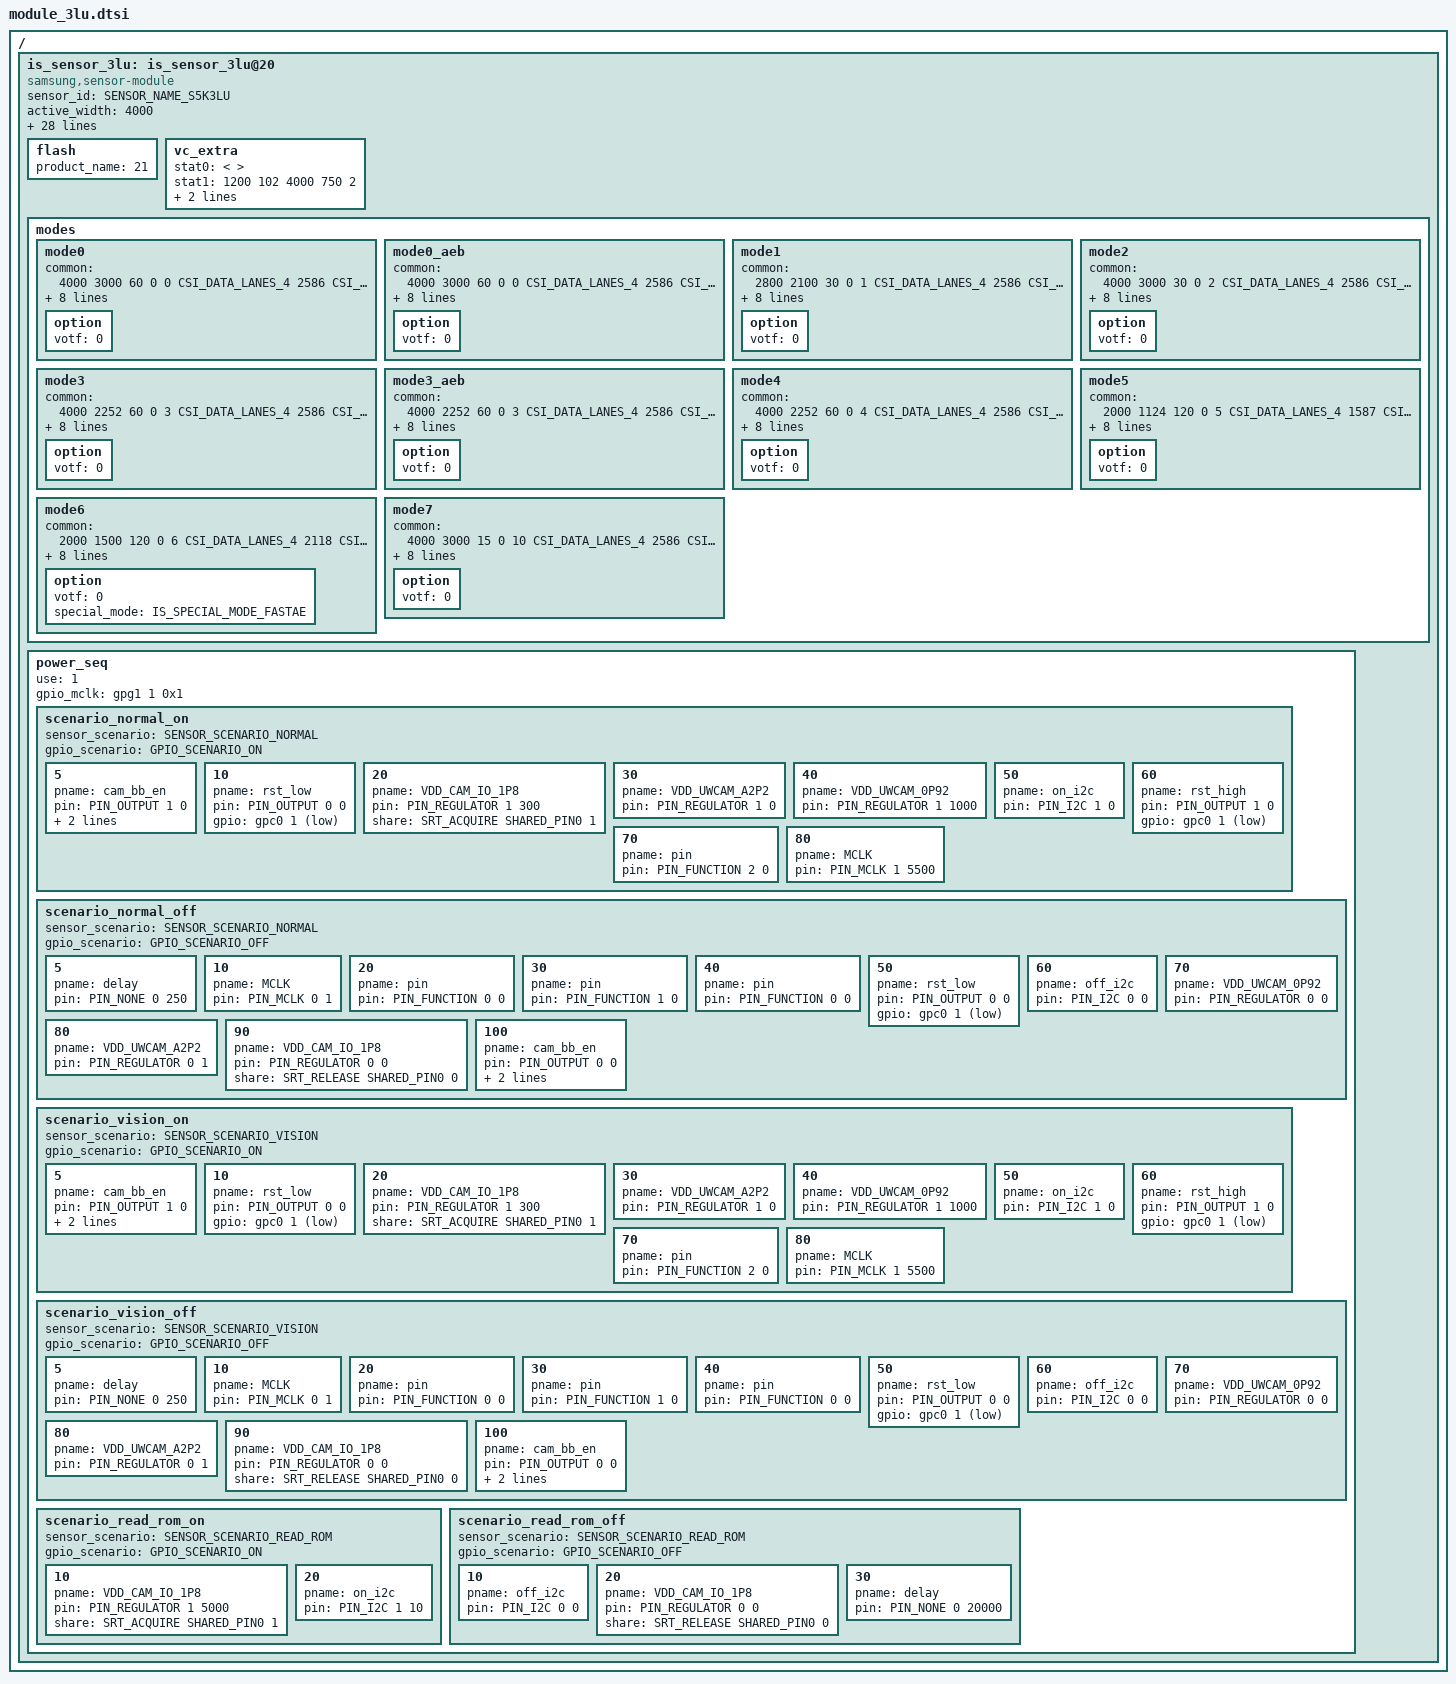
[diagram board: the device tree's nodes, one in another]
/*
 * SAMSUNG EXYNOSxxxx board camera device tree source
 *
 * Copyright (c) 2024 Samsung Electronics Co., Ltd.
 *		http://www.samsung.com
 *
 * This program is free software; you can redistribute it and/or modify
 * it under the terms of the GNU General Public License version 2 as
 * published by the Free Software Foundation.
 */

#include <dt-bindings/camera/exynos_is_dt.h>

/ {
	fragment@camera {
		target-path = "/";
		__overlay__ {
			is_sensor_3lu: is_sensor_3lu@20 {
				compatible = "samsung,sensor-module";

				/* common */
				sensor_id = <SENSOR_NAME_S5K3LU>;
				active_width = <4000>;
				active_height = <3000>;
				margin_left = <0>;
				margin_right = <0>;
				margin_top = <0>;
				margin_bottom = <0>;
				max_framerate = <240>;
				bitwidth = <10>;
				use_retention_mode = <SENSOR_RETENTION_UNSUPPORTED>;
				sensor_maker = "SLSI";
				sensor_name = "S5K3LU";
				setfile_name = "setfile_3lu.bin";
				pinning_setfile;
				status = "okay";

				/* board */
				pinctrl-names = "pin0", "pin1", "pin2", "release";
				pinctrl-0 = <>;
				pinctrl-1 = <&sensor_mclk1_out>;
				pinctrl-2 = <&sensor_mclk1_fn>;
				pinctrl-3 = <>;

				position = <4>;	/* Rear:0. Front:1. Rear_sub:2. Secure:3. */
				id = <4>; /* is_sensor id */
				mclk_ch = <1>;
				mclk_freq = <19200>;
				sensor_i2c_ch = <4>; /* SENSOR_CONTROL_I2C4 */

				/* vendor */
				rom_id = <2>;
				rom_cal_index = <0>;

				rom_dualcal_id = <2>;
				rom_dualcal_index = <0>;

				use_dualcal_from_file;
				dual_cal_file_name = "rear3_dualcal_param.bin";
				flash {
					product_name = <21>; /* AW36518 */
				};
#if 0
				ois {
					product_name = <100>; /* NOTHING */
				};
#endif
				vc_extra {
					/* ex) statX = <stat_type, sensor_mode, max_width, max_height, max_element> */
					stat0 = </* not available */>;									/* VC_BUF_DATA_TYPE_SENSOR_STAT1 */
					stat1 = </*VC_STAT_TYPE_PDP_4_1_PDAF_STAT0*/ 1200 /*VC_SENSOR_MODE_2PD_MODE3*/ 102 4000 750 2>;	/* VC_BUF_DATA_TYPE_GENERAL_STAT1 */
					stat2 = </* not available */>;									/* VC_BUF_DATA_TYPE_SENSOR_STAT2 */
					stat3 = </*VC_STAT_TYPE_PDP_4_1_PDAF_STAT1*/ 1201 /*VC_SENSOR_MODE_2PD_MODE3*/ 102 4000 750 2>;	/* VC_BUF_DATA_TYPE_GENERAL_STAT2 */
				};

				/* sensor modes */
				/*
				SENSOR_3LU_4000X3000_60FPS_10BIT = 0, // A-01-A
				SENSOR_3LU_2800X2100_30FPS_10BIT = 1, // A-01-D
				SENSOR_3LU_4000X3000_30FPS_ADC = 2, // A-04-A
				SENSOR_3LU_4000X2252_60FPS_10BIT = 3, // A-09-A
				SENSOR_3LU_4000X2252_60FPS_ADC = 4, // A-12
				SENSOR_3LU_2000X1124_120FPS_10BIT = 5, // B-01
				SENSOR_3LU_2000X1500_120FPS_FAST_AE = 6, // C-02
				SENSOR_3LU_4000X3000_15FPS_10BIT_LN4 = 10, // A-07
				*/
				modes {
					/* common = <width, height, fps, settle, mode, lane, speed, interleave, lrte, pd_mode> */
					/* vcX = <map, hwformat, width, height, hwformat, type, width, height> */
					mode0 { /* SENSOR_3LU_4000X3000_60FPS_10BIT = 0 */ /* A-01-A */
						common = <4000 3000 60 0 0 CSI_DATA_LANES_4 2586 CSI_MODE_VC_DT LRTE_ENABLE PD_NONE>;
						vc0 = </* in */ 0 HW_FORMAT_RAW10 DATA_IMG 4000 3000	/* out */ HW_FORMAT_RAW10 VC_NOTHING 4000 3000>;
						vc1 = </* in */ 1 HW_FORMAT_UNKNOWN DATA_NONE 0 0		/* out */ HW_FORMAT_UNKNOWN VC_NOTHING 0 0>;
						vc2 = </* in */ 0 HW_FORMAT_EMBEDDED_8BIT_POTF DATA_EMB 4000 22		/* out */ HW_FORMAT_UNKNOWN VC_NOTHING 0 0>;
						vc3 = </* in */ 2 HW_FORMAT_UNKNOWN DATA_NONE 0 0		/* out */ HW_FORMAT_UNKNOWN VC_NOTHING 0 0>;
						option { votf = <0>; };
					};
					mode0_aeb { /* SENSOR_3LU_4000X3000_60FPS_10BIT = 0 */ /* A-01-A */ /* AEB */
						common = <4000 3000 60 0 0 CSI_DATA_LANES_4 2586 CSI_MODE_VC_DT LRTE_ENABLE PD_NONE EX_AEB>;
						vc0 = </* in */ 0 HW_FORMAT_RAW10 DATA_IMG 4000 3000	/* out */ HW_FORMAT_RAW10 VC_NOTHING 4000 3000>;
						vc1 = </* in */ 2 HW_FORMAT_RAW10 DATA_IMG 4000 3000	/* out */ HW_FORMAT_RAW10 VC_NOTHING 4000 3000>;
						vc2 = </* in */ 0 HW_FORMAT_EMBEDDED_8BIT_POTF DATA_EMB 4000 22		/* out */ HW_FORMAT_UNKNOWN VC_NOTHING 0 0>;
						vc3 = </* in */ 2 HW_FORMAT_EMBEDDED_8BIT_POTF DATA_EMB 4000 22		/* out */ HW_FORMAT_UNKNOWN VC_NOTHING 0 0>;
						option { votf = <0>; };
					};
					mode1 { /* SENSOR_3LU_2800X2100_30FPS_10BIT = 1 */ /* A-01-D */
						common = <2800 2100 30 0 1 CSI_DATA_LANES_4 2586 CSI_MODE_VC_DT LRTE_ENABLE PD_NONE>;
						vc0 = </* in */ 0 HW_FORMAT_RAW10 DATA_IMG 2800 2100	/* out */ HW_FORMAT_RAW10 VC_NOTHING 2800 2100>;
						vc1 = </* in */ 1 HW_FORMAT_UNKNOWN DATA_NONE 0 0		/* out */ HW_FORMAT_UNKNOWN VC_NOTHING 0 0>;
						vc2 = </* in */ 0 HW_FORMAT_EMBEDDED_8BIT_POTF DATA_EMB 2800 24		/* out */ HW_FORMAT_UNKNOWN VC_NOTHING 0 0>;
						vc3 = </* in */ 2 HW_FORMAT_UNKNOWN DATA_NONE 0 0		/* out */ HW_FORMAT_UNKNOWN VC_NOTHING 0 0>;
						option { votf = <0>; };
					};
					mode2 { /* SENSOR_3LU_4000X3000_30FPS_ADC = 2 /* A-04-A */
						common = <4000 3000 30 0 2 CSI_DATA_LANES_4 2586 CSI_MODE_VC_DT LRTE_ENABLE PD_NONE>;
						vc0 = </* in */ 0 HW_FORMAT_RAW12 DATA_IMG 4000 3000	/* out */ HW_FORMAT_RAW12 VC_NOTHING 4000 3000>;
						vc1 = </* in */ 1 HW_FORMAT_UNKNOWN DATA_NONE 0 0		/* out */ HW_FORMAT_UNKNOWN VC_NOTHING 0 0>;
						vc2 = </* in */ 0 HW_FORMAT_EMBEDDED_8BIT_POTF DATA_EMB 4000 22		/* out */ HW_FORMAT_UNKNOWN VC_NOTHING 0 0>;
						vc3 = </* in */ 2 HW_FORMAT_UNKNOWN DATA_NONE 0 0		/* out */ HW_FORMAT_UNKNOWN VC_NOTHING 0 0>;
						option { votf = <0>; };
					};
					mode3 { /* SENSOR_3LU_4000X2252_60FPS_10BIT = 3 /* A-09-A */
						common = <4000 2252 60 0 3 CSI_DATA_LANES_4 2586 CSI_MODE_VC_DT LRTE_ENABLE PD_NONE>;
						vc0 = </* in */ 0 HW_FORMAT_RAW10 DATA_IMG 4000 2252	/* out */ HW_FORMAT_RAW10 VC_NOTHING 4000 2252>;
						vc1 = </* in */ 1 HW_FORMAT_UNKNOWN DATA_NONE 0 0		/* out */ HW_FORMAT_UNKNOWN VC_NOTHING 0 0>;
						vc2 = </* in */ 0 HW_FORMAT_EMBEDDED_8BIT_POTF DATA_EMB 4000 20		/* out */ HW_FORMAT_UNKNOWN VC_NOTHING 0 0>;
						vc3 = </* in */ 2 HW_FORMAT_UNKNOWN DATA_NONE 0 0		/* out */ HW_FORMAT_UNKNOWN VC_NOTHING 0 0>;
						option { votf = <0>; };
					};
					mode3_aeb { /* SENSOR_3LU_4000X2252_60FPS_10BIT = 3 /* A-09-A */ /* AEB */
						common = <4000 2252 60 0 3 CSI_DATA_LANES_4 2586 CSI_MODE_VC_DT LRTE_ENABLE PD_NONE EX_AEB>;
						vc0 = </* in */ 0 HW_FORMAT_RAW10 DATA_IMG 4000 2252	/* out */ HW_FORMAT_RAW10 VC_NOTHING 4000 2252>;
						vc1 = </* in */ 2 HW_FORMAT_RAW10 DATA_IMG 4000 2252	/* out */ HW_FORMAT_RAW10 VC_NOTHING 4000 2252>;
						vc2 = </* in */ 0 HW_FORMAT_EMBEDDED_8BIT_POTF DATA_EMB 4000 20		/* out */ HW_FORMAT_UNKNOWN VC_NOTHING 0 0>;
						vc3 = </* in */ 2 HW_FORMAT_EMBEDDED_8BIT_POTF DATA_EMB 4000 20		/* out */ HW_FORMAT_UNKNOWN VC_NOTHING 0 0>;
						option { votf = <0>; };
					};
					mode4 { /* SENSOR_3LU_4000X2252_60FPS_ADC = 4 /* A-12 */
						common = <4000 2252 60 0 4 CSI_DATA_LANES_4 2586 CSI_MODE_VC_DT LRTE_ENABLE PD_NONE>;
						vc0 = </* in */ 0 HW_FORMAT_RAW12 DATA_IMG 4000 2252	/* out */ HW_FORMAT_RAW12 VC_NOTHING 4000 2252>;
						vc1 = </* in */ 1 HW_FORMAT_UNKNOWN DATA_NONE 0 0		/* out */ HW_FORMAT_UNKNOWN VC_NOTHING 0 0>;
						vc2 = </* in */ 0 HW_FORMAT_EMBEDDED_8BIT_POTF DATA_EMB 4000 20		/* out */ HW_FORMAT_UNKNOWN VC_NOTHING 0 0>;
						vc3 = </* in */ 2 HW_FORMAT_UNKNOWN DATA_NONE 0 0		/* out */ HW_FORMAT_UNKNOWN VC_NOTHING 0 0>;
						option { votf = <0>; };
					};
					mode5 { /* SENSOR_3LU_2000X1124_120FPS_10BIT = 5 */ /* B-01 */
						common = <2000 1124 120 0 5 CSI_DATA_LANES_4 1587 CSI_MODE_VC_DT LRTE_ENABLE PD_NONE>;
						vc0 = </* in */ 0 HW_FORMAT_RAW10 DATA_IMG 2000 1124	/* out */ HW_FORMAT_RAW10 VC_NOTHING 2000 1124>;
						vc1 = </* in */ 1 HW_FORMAT_UNKNOWN DATA_NONE 0 0		/* out */ HW_FORMAT_UNKNOWN VC_NOTHING 0 0>;
						vc2 = </* in */ 0 HW_FORMAT_EMBEDDED_8BIT_POTF DATA_EMB 2000 22		/* out */ HW_FORMAT_UNKNOWN VC_NOTHING 0 0>;
						vc3 = </* in */ 2 HW_FORMAT_UNKNOWN DATA_NONE 0 0		/* out */ HW_FORMAT_UNKNOWN VC_NOTHING 0 0>;
						option { votf = <0>; };
					};
					mode6 { /* SENSOR_3LU_2000X1500_120FPS_FAST_AE = 6 */ /* C-02 */
						common = <2000 1500 120 0 6 CSI_DATA_LANES_4 2118 CSI_MODE_VC_DT LRTE_ENABLE PD_NONE>;
						vc0 = </* in */ 0 HW_FORMAT_RAW10 DATA_IMG 2000 1500	/* out */ HW_FORMAT_RAW10 VC_NOTHING 2000 1500>;
						vc1 = </* in */ 1 HW_FORMAT_UNKNOWN DATA_NONE 0 0		/* out */ HW_FORMAT_UNKNOWN VC_NOTHING 0 0>;
						vc2 = </* in */ 0 HW_FORMAT_EMBEDDED_8BIT_POTF DATA_EMB 2000 8		/* out */ HW_FORMAT_UNKNOWN VC_NOTHING 0 0>;
						vc3 = </* in */ 2 HW_FORMAT_UNKNOWN DATA_NONE 0 0		/* out */ HW_FORMAT_UNKNOWN VC_NOTHING 0 0>;
						option { votf = <0>; special_mode = <IS_SPECIAL_MODE_FASTAE>; };
					};
					mode7 { /* SENSOR_3LU_4000X3000_15FPS_10BIT_LN4 = 10 */ /* A-07 */
						common = <4000 3000 15 0 10 CSI_DATA_LANES_4 2586 CSI_MODE_VC_DT LRTE_ENABLE PD_NONE EX_LN>;
						vc0 = </* in */ 0 HW_FORMAT_RAW10 DATA_IMG 4000 3000	/* out */ HW_FORMAT_RAW10 VC_NOTHING 4000 3000>;
						vc1 = </* in */ 1 HW_FORMAT_UNKNOWN DATA_NONE 0 0		/* out */ HW_FORMAT_UNKNOWN VC_NOTHING 0 0>;
						vc2 = </* in */ 0 HW_FORMAT_EMBEDDED_8BIT_POTF DATA_EMB 4000 22		/* out */ HW_FORMAT_UNKNOWN VC_NOTHING 0 0>;
						vc3 = </* in */ 2 HW_FORMAT_UNKNOWN DATA_NONE 0 0		/* out */ HW_FORMAT_UNKNOWN VC_NOTHING 0 0>;
						option { votf = <0>; };
					};

				};

				power_seq {
					use = <1>;
					gpio_mclk = <&gpg1 1 0x1>;
					scenario_normal_on {
						sensor_scenario = <SENSOR_SCENARIO_NORMAL>;
						gpio_scenario = <GPIO_SCENARIO_ON>;

						/* A start node number should be over the 10 for reserved number 0~9. */
						/* pname = "name"; pin = <act value delay voltage>; gpio = <gpx# # 0x1>; */
						5 { pname = "cam_bb_en"; pin = <PIN_OUTPUT 1 0>; gpio = <&gpc1 0 0x1>; share = <SRT_ACQUIRE SHARED_PIN1 1>; };
						10 { pname = "rst_low"; pin = <PIN_OUTPUT 0 0>; gpio = <&gpc0 1 0x1>; };
						20 { pname = "VDD_CAM_IO_1P8"; pin = <PIN_REGULATOR 1 300>; share = <SRT_ACQUIRE SHARED_PIN0 1>; };
						30 { pname = "VDD_UWCAM_A2P2"; pin = <PIN_REGULATOR 1 0>; };
						40 { pname = "VDD_UWCAM_0P92"; pin = <PIN_REGULATOR 1 1000>; };
						50 { pname = "on_i2c"; pin = <PIN_I2C 1 0>; };
						60 { pname = "rst_high"; pin = <PIN_OUTPUT 1 0>; gpio = <&gpc0 1 0x1>; };
						70 { pname = "pin"; pin = <PIN_FUNCTION 2 0>; };
						80 { pname = "MCLK"; pin = <PIN_MCLK 1 5500>; };
					};

					scenario_normal_off {
						sensor_scenario = <SENSOR_SCENARIO_NORMAL>;
						gpio_scenario = <GPIO_SCENARIO_OFF>;

						/* A start node number should be over the 10 for reserved number 0~9. */
						/* pname = "name"; pin = <act value delay voltage>; gpio = <gpx# # 0x1>; */
						5 { pname = "delay"; pin = <PIN_NONE 0 250>; };
						10 { pname = "MCLK"; pin = <PIN_MCLK 0 1>; };
						20 { pname = "pin"; pin = <PIN_FUNCTION 0 0>; };
						30 { pname = "pin"; pin = <PIN_FUNCTION 1 0>; };
						40 { pname = "pin"; pin = <PIN_FUNCTION 0 0>; };
						50 { pname = "rst_low"; pin = <PIN_OUTPUT 0 0>; gpio = <&gpc0 1 0x1>; };
						60 { pname = "off_i2c"; pin = <PIN_I2C 0 0>; };
						70 { pname = "VDD_UWCAM_0P92"; pin = <PIN_REGULATOR 0 0>; };
						80 { pname = "VDD_UWCAM_A2P2"; pin = <PIN_REGULATOR 0 1>; };
						90 { pname = "VDD_CAM_IO_1P8"; pin = <PIN_REGULATOR 0 0>; share = <SRT_RELEASE SHARED_PIN0 0>; };
						100 { pname = "cam_bb_en"; pin = <PIN_OUTPUT 0 0>; gpio = <&gpc1 0 0x1>; share = <SRT_RELEASE SHARED_PIN1 0>; };
					};

					scenario_vision_on {
						sensor_scenario = <SENSOR_SCENARIO_VISION>;
						gpio_scenario = <GPIO_SCENARIO_ON>;

						/* A start node number should be over the 10 for reserved number 0~9. */
						/* pname = "name"; pin = <act value delay voltage>; gpio = <gpx# # 0x1>; */
						5 { pname = "cam_bb_en"; pin = <PIN_OUTPUT 1 0>; gpio = <&gpc1 0 0x1>; share = <SRT_ACQUIRE SHARED_PIN1 1>; };
						10 { pname = "rst_low"; pin = <PIN_OUTPUT 0 0>; gpio = <&gpc0 1 0x1>; };
						20 { pname = "VDD_CAM_IO_1P8"; pin = <PIN_REGULATOR 1 300>; share = <SRT_ACQUIRE SHARED_PIN0 1>; };
						30 { pname = "VDD_UWCAM_A2P2"; pin = <PIN_REGULATOR 1 0>; };
						40 { pname = "VDD_UWCAM_0P92"; pin = <PIN_REGULATOR 1 1000>; };
						50 { pname = "on_i2c"; pin = <PIN_I2C 1 0>; };
						60 { pname = "rst_high"; pin = <PIN_OUTPUT 1 0>; gpio = <&gpc0 1 0x1>; };
						70 { pname = "pin"; pin = <PIN_FUNCTION 2 0>; };
						80 { pname = "MCLK"; pin = <PIN_MCLK 1 5500>; };
					};

					scenario_vision_off {
						sensor_scenario = <SENSOR_SCENARIO_VISION>;
						gpio_scenario = <GPIO_SCENARIO_OFF>;

						/* A start node number should be over the 10 for reserved number 0~9. */
						/* pname = "name"; pin = <act value delay voltage>; gpio = <gpx# # 0x1>; */
						5 { pname = "delay"; pin = <PIN_NONE 0 250>; };
						10 { pname = "MCLK"; pin = <PIN_MCLK 0 1>; };
						20 { pname = "pin"; pin = <PIN_FUNCTION 0 0>; };
						30 { pname = "pin"; pin = <PIN_FUNCTION 1 0>; };
						40 { pname = "pin"; pin = <PIN_FUNCTION 0 0>; };
						50 { pname = "rst_low"; pin = <PIN_OUTPUT 0 0>; gpio = <&gpc0 1 0x1>; };
						60 { pname = "off_i2c"; pin = <PIN_I2C 0 0>; };
						70 { pname = "VDD_UWCAM_0P92"; pin = <PIN_REGULATOR 0 0>; };
						80 { pname = "VDD_UWCAM_A2P2"; pin = <PIN_REGULATOR 0 1>; };
						90 { pname = "VDD_CAM_IO_1P8"; pin = <PIN_REGULATOR 0 0>; share = <SRT_RELEASE SHARED_PIN0 0>; };
						100 { pname = "cam_bb_en"; pin = <PIN_OUTPUT 0 0>; gpio = <&gpc1 0 0x1>; share = <SRT_RELEASE SHARED_PIN1 0>; };
					};

					scenario_read_rom_on {
						sensor_scenario = <SENSOR_SCENARIO_READ_ROM>;
						gpio_scenario = <GPIO_SCENARIO_ON>;

						/* A start node number should be over the 10 for reserved number 0~9. */
						/* pname = "name"; pin = <act value delay voltage>; gpio = <gpx# # 0x1>; */
						10 { pname = "VDD_CAM_IO_1P8"; pin = <PIN_REGULATOR 1 5000>; share = <SRT_ACQUIRE SHARED_PIN0 1>; };
						20 { pname = "on_i2c"; pin = <PIN_I2C 1 10>; };
					};

					scenario_read_rom_off {
						sensor_scenario = <SENSOR_SCENARIO_READ_ROM>;
						gpio_scenario = <GPIO_SCENARIO_OFF>;

						/* A start node number should be over the 10 for reserved number 0~9. */
						/* pname = "name"; pin = <act value delay voltage>; gpio = <gpx# # 0x1>; */
						10 { pname = "off_i2c"; pin = <PIN_I2C 0 0>; };
						20 { pname = "VDD_CAM_IO_1P8"; pin = <PIN_REGULATOR 0 0>; share = <SRT_RELEASE SHARED_PIN0 0>; };
						30 { pname = "delay"; pin = <PIN_NONE 0 20000>; };
					};
				};
			};
		}; /* end of __overlay__ */
	}; /* end of fragment */
}; /* end of root */
